# M3U6 register map
File version: 2.0.2.11
Registers are 32-bit, read-write, reset 0x0 unless marked. A register's access mark holds for its fields unless they carry their own. Offsets are from the block's base; [hi:lo] are bit positions; {n}, {i} and the like mark numbered series; 'fields as' and 'values as' point back to an identical list.

## OFD — Oscillation Frequency Detector (OFD)
Base 0x40040800
0x00 CR1 reset 0x6 — OFD Control Register 1
  [7:0] OFDWEN
0x04 CR2 — OFD Control Register 2
  [7:0] OFDEN
0x08 MN — OFD Lower Detection Frequency Setting Register
  [7:0] OFDMN
0x10 MX — OFD Higher Detection Frequency Setting Register
  [7:0] OFDMX
0x18 RST reset 0x1 — OFD Reset Enable Control Register
  [0] OFDRSTEN
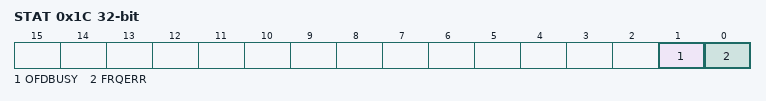
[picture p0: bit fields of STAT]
0x1C STAT ro — OFD Status Register
  [1] OFDBUSY, [0] FRQERR

## VD — Voltage Detection Circuit (VD)
Base 0x40040900
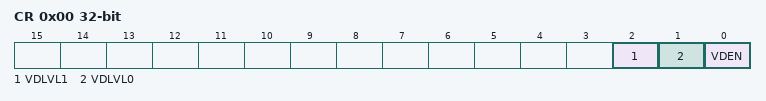
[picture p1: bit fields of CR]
0x00 CR — Voltage Detection Control Register
  [2] VDLVL1, [1] VDLVL0, [0] VDEN
0x04 SR ro — Voltage Detection Status Register
  [0] VDSR

## MTPD0 — 16-bit Multi-Purpose Timer (MPT-PMD)
Base 0x40050400
Same registers: MTPD1 0x40050480
0x00 MDEN — PMD Enable Register
  [0] PWMEN
0x04 PORTMD — Port Output Mode Register
  [1:0] PORTMD
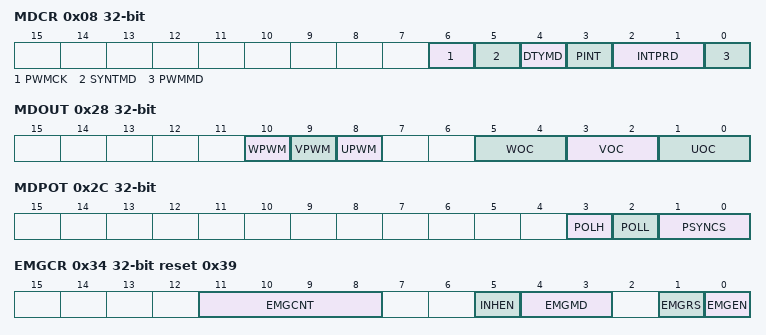
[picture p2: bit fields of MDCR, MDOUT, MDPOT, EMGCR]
0x08 MDCR — PMD Control Register
  [6] PWMCK, [5] SYNTMD, [4] DTYMD, [3] PINT, [2:1] INTPRD, [0] PWMMD
0x0C CNTSTA ro — PWM Counter Status Register
  [0] UPDWN
0x10 MDCNT ro — PWM Counter Register
  [0] MDCNT
0x14 MDPRD — PWM Period Register
  [14:0] MDPRD
0x18 CMPU — PWM Compare Register
  [14:0] CMPU
0x1C CMPV — PWM Compare Register
  [14:0] CMPV
0x20 CMPW — PWM Compare Register
  [14:0] CMPW
0x28 MDOUT — PMD Output Control Register
  [10] WPWM, [9] VPWM, [8] UPWM, [5:4] WOC, [3:2] VOC, [1:0] UOC
0x2C MDPOT — PMD Output Setting Register
  [3] POLH, [2] POLL, [1:0] PSYNCS
0x30 EMGREL wo — EMG Release Register
  [7:0] EMGREL
0x34 EMGCR reset 0x39 — EMG Control Register
  [11:8] EMGCNT, [5] INHEN, [4:3] EMGMD, [1] EMGRS wo, [0] EMGEN
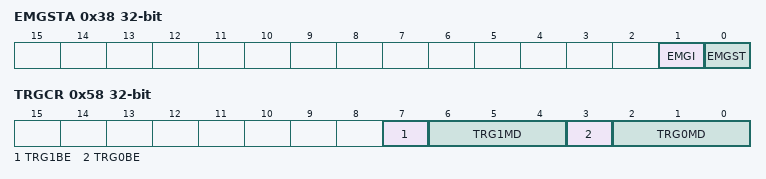
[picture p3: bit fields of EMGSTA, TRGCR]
0x38 EMGSTA ro (reset mask 0xFFFFFFFD) — EMG Status Register
  [1] EMGI, [0] EMGST
0x44 DTR — Dead Time Register
  [7:0] DTR
0x48 TRGCMP0 — Trigger Compare Register 0
  [15:0] TRGCMP0
0x4C TRGCMP1 — Trigger Compare Register 1
  [15:0] TRGCMP1
0x58 TRGCR — Trigger Control Register
  [7] TRG1BE, [6:4] TRG1MD, [3] TRG0BE, [2:0] TRG0MD
0x5C TRGMD — Trigger Output Mode Setting Register
  [0] EMGTGE

## MT0 — 16-bit Multi-Purpose Timer (MPT-TMR_IGBT)
Base 0x40050800
Same registers: MT1 0x40050880, MT2 0x40050900
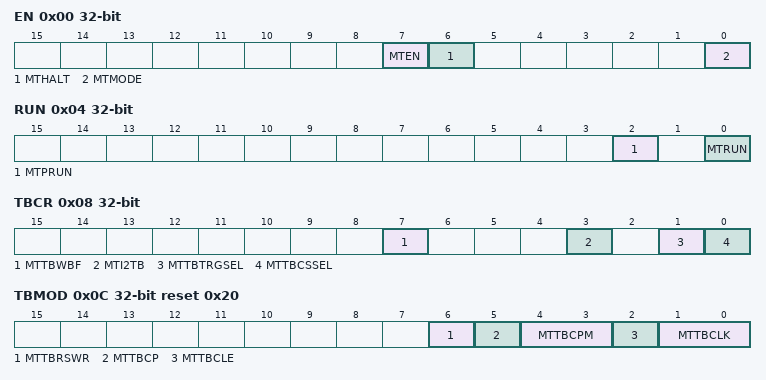
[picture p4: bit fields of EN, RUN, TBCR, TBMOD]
0x00 EN — MPT Enable Register
  [7] MTEN, [6] MTHALT, [0] MTMODE
0x04 RUN — MPT RUN Register
  [2] MTPRUN, [0] MTRUN
0x08 TBCR — MPT Control Register
  [7] MTTBWBF, [3] MTI2TB, [1] MTTBTRGSEL, [0] MTTBCSSEL
0x0C TBMOD reset 0x20 — MPT Mode Register
  [6] MTTBRSWR, [5] MTTBCP wo, [4:3] MTTBCPM, [2] MTTBCLE, [1:0] MTTBCLK
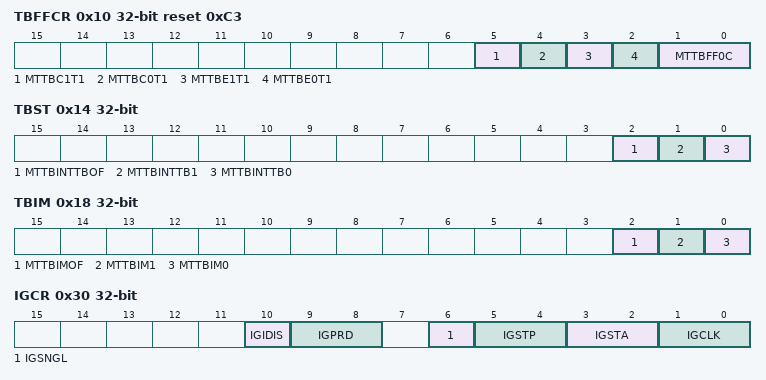
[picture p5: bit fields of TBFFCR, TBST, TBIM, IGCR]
0x10 TBFFCR reset 0xC3 — MPT Flip-Flop Control Register
  [5] MTTBC1T1, [4] MTTBC0T1, [3] MTTBE1T1, [2] MTTBE0T1, [1:0] MTTBFF0C
0x14 TBST ro — MPT Status Register
  [2] MTTBINTTBOF, [1] MTTBINTTB1, [0] MTTBINTTB0
0x18 TBIM — MPT Interrupt Mask Register
  [2] MTTBIMOF, [1] MTTBIM1, [0] MTTBIM0
0x1C TBUC ro — MPT Read Capture Register
  [15:0] MTUC
0x20 RG0 — MPT RG0 Timer Register
  [15:0] MTRG0
0x24 RG1 — MPT RG1 Timer Register
  [15:0] MTRG1
0x28 CP0 ro — MPT CP0 Capture Register
  [15:0] MTCP0
0x2C CP1 ro — MPT CP1 Capture Register
  [15:0] MTCP1
0x30 IGCR — IGBT Control Register
  [10] IGIDIS, [9:8] IGPRD, [6] IGSNGL, [5:4] IGSTP, [3:2] IGSTA, [1:0] IGCLK
0x34 IGRESTA wo — IGBT Timer Restart Register
  [0] IGRESTA
0x38 IGST ro — IGBT Timer Status Register
  [0] IGST
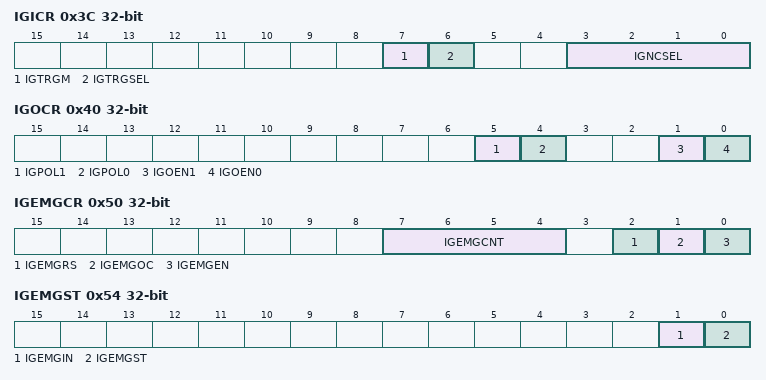
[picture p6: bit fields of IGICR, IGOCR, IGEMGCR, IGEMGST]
0x3C IGICR — IGBT Input Control Register
  [7] IGTRGM, [6] IGTRGSEL, [3:0] IGNCSEL
0x40 IGOCR — IGBT Output Control Register
  [5] IGPOL1, [4] IGPOL0, [1] IGOEN1, [0] IGOEN0
{0x3C+4i} IGRG{i} (i=2..4) — IGBT RG{i} Timer Register
  [15:0] IGRG{i}
0x50 IGEMGCR — IGBT EMG Control Register
  [7:4] IGEMGCNT, [2] IGEMGRS wo, [1] IGEMGOC, [0] IGEMGEN
0x54 IGEMGST ro — IGBT EMG Status Register
  [1] IGEMGIN, [0] IGEMGST

## DMAC — Single Master DMA Controller (DMAC)
Base 0x40080000
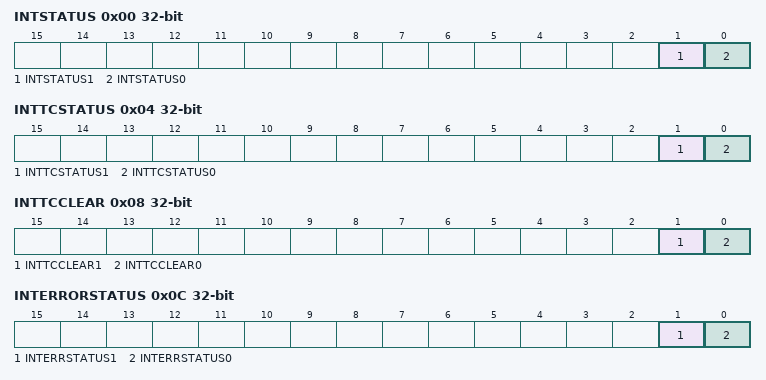
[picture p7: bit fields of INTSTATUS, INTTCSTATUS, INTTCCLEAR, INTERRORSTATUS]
0x00 INTSTATUS ro — DMAC Interrupt Status Register
  [1] INTSTATUS1, [0] INTSTATUS0
0x04 INTTCSTATUS ro — DMAC Interrupt Terminal Count Status Register
  [1] INTTCSTATUS1, [0] INTTCSTATUS0
0x08 INTTCCLEAR wo — DMAC Interrupt Terminal Count Clear Register
  [1] INTTCCLEAR1, [0] INTTCCLEAR0
0x0C INTERRORSTATUS ro — DMAC Interrupt Error Status Register
  [1] INTERRSTATUS1, [0] INTERRSTATUS0
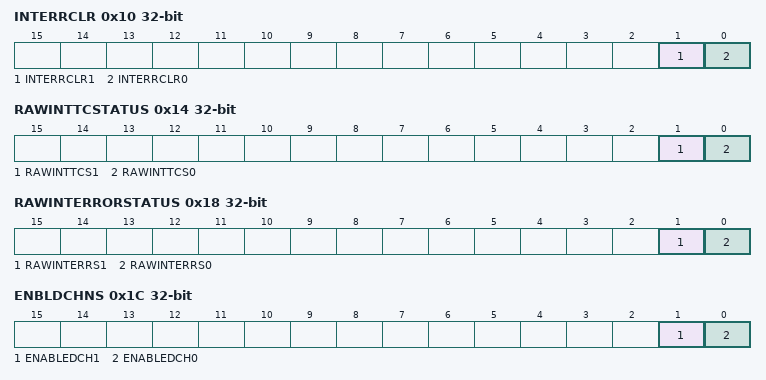
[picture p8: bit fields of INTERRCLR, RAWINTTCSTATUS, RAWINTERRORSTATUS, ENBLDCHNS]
0x10 INTERRCLR wo — DMAC Interrupt Error Clear Register
  [1] INTERRCLR1, [0] INTERRCLR0
0x14 RAWINTTCSTATUS ro — DMAC Raw Interrupt Terminal Count Status Register
  [1] RAWINTTCS1, [0] RAWINTTCS0
0x18 RAWINTERRORSTATUS ro — DMAC Raw Error Interrupt Status Register
  [1] RAWINTERRS1, [0] RAWINTERRS0
0x1C ENBLDCHNS ro — DMAC Enabled Channel Register
  [1] ENABLEDCH1, [0] ENABLEDCH0
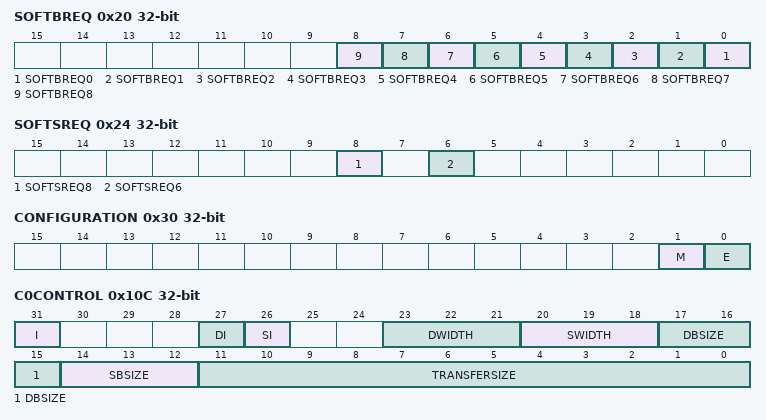
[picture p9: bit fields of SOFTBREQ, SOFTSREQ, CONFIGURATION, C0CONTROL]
0x20 SOFTBREQ — DMAC Software Burst Request Register
  [n] SOFTBREQ{n} (n=0..8)
0x24 SOFTSREQ — DMAC Software Single Request Register
  [8] SOFTSREQ8, [6] SOFTSREQ6
0x30 CONFIGURATION — DMAC Configuration Register
  [1] M, [0] E
0x100 C0SRCADDR — DMAC Channel0 Source Address Register
  [31:0] SRCADDR
0x104 C0DESTADDR — DMAC Channel0 Destination Address Register
  [31:0] DESTADDR
0x108 C0LLI (reset mask 0x7FFFFFFE) — DMAC Channel0 Linked List Item Register
  [31:2] LLI
0x10C C0CONTROL — DMAC Channel0 Control Register
  [31] I, [27] DI, [26] SI, [23:21] DWIDTH, [20:18] SWIDTH, [17:15] DBSIZE, [14:12] SBSIZE, [11:0] TRANSFERSIZE
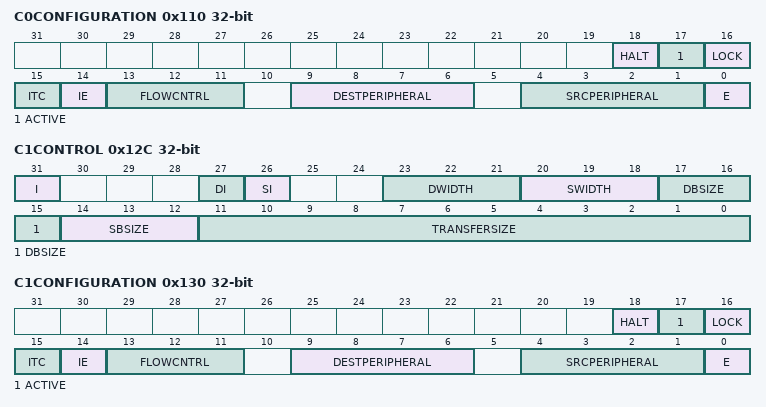
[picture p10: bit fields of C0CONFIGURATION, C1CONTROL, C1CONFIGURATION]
0x110 C0CONFIGURATION — DMAC Channel0 Configuration Register
  [18] HALT, [17] ACTIVE ro, [16] LOCK, [15] ITC, [14] IE, [13:11] FLOWCNTRL, [9:6] DESTPERIPHERAL, [4:1] SRCPERIPHERAL, [0] E
0x120 C1SRCADDR — DMAC Channel1 Source Address Register
  [31:0] SRCADDR
0x124 C1DESTADDR — DMAC Channel1 Destination Address Register
  [31:0] DESTADDR
0x128 C1LLI (reset mask 0x7FFFFFFE) — DMAC Channel1 Linked List Item Register
  [31:2] LLI
0x12C C1CONTROL — DMAC Channel1Control Register
  fields as C0CONTROL
0x130 C1CONFIGURATION — DMAC Channel1 Configuration Register
  fields as C0CONFIGURATION

## SSP0 — Synchronous Serial Port (SSP)
Base 0x400C0000
Same registers: SSP1 0x400C1000
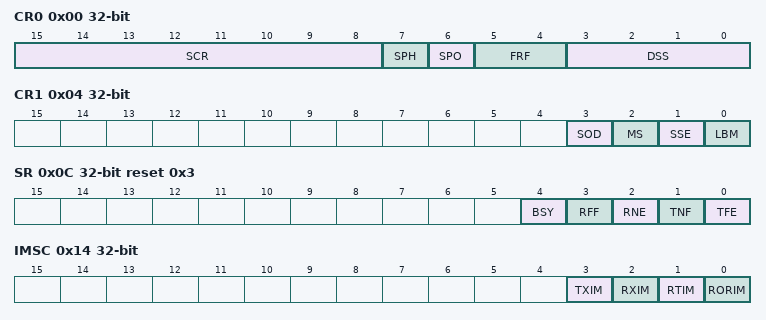
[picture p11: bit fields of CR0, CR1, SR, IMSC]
0x00 CR0 — SSP Control Register 0
  [15:8] SCR, [7] SPH, [6] SPO, [5:4] FRF, [3:0] DSS
0x04 CR1 — SSP Control Register 1
  [3] SOD, [2] MS, [1] SSE, [0] LBM
0x08 DR — SSP Data Register
  [15:0] DATA
0x0C SR ro reset 0x3 — SSP Status Register
  [4] BSY, [3] RFF, [2] RNE, [1] TNF, [0] TFE
0x10 CPSR — SSP Clock Prescaler Register
  [7:0] CPSDVSR
0x14 IMSC — SSP Interrupt Mask Set and Clear Register
  [3] TXIM, [2] RXIM, [1] RTIM, [0] RORIM
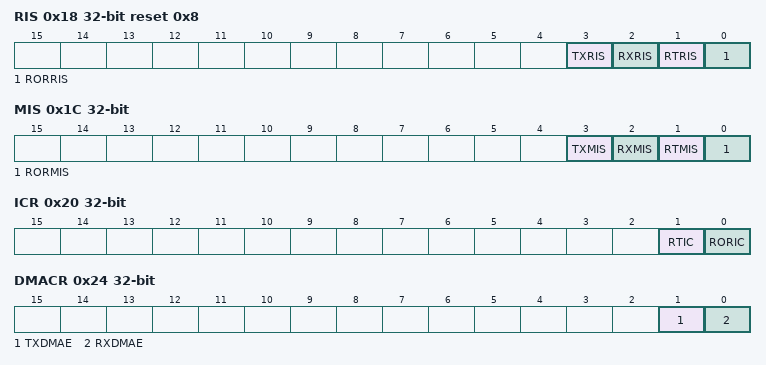
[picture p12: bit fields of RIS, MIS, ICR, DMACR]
0x18 RIS ro reset 0x8 — SSP Raw Interrupt Status Register
  [3] TXRIS, [2] RXRIS, [1] RTRIS, [0] RORRIS
0x1C MIS ro — SSP Masked Interrupt Status Register
  [3] TXMIS, [2] RXMIS, [1] RTMIS, [0] RORMIS
0x20 ICR wo reset not defined — SSP Interrupt Clear Register
  [1] RTIC, [0] RORIC
0x24 DMACR — SSP DMA Control Register
  [1] TXDMAE, [0] RXDMAE

## FC — Flash Control (FC)
Base 0x41FFF010
0x00 SECBIT reset 0x1 — FC Security Bit Register
  [0] SECBIT
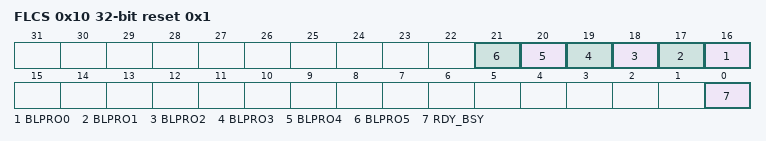
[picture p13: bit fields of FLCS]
0x10 FLCS ro reset 0x1 (reset mask 0xFFC0FFFF) — FC FLASH Control Register
  [n+16] BLPRO{n} (n=0..5), [0] RDY_BSY
